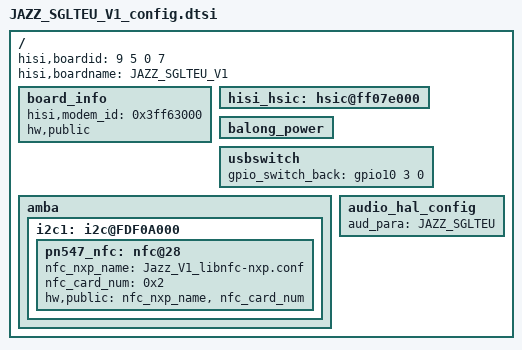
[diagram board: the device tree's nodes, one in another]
/*
 * Hisilicon Ltd.
 *
 * A15x4 A7x4
 *
 * It is only a demo for hisilicon hi3630 board. You show change the
 * address of each node according to datasheet.
 */


/include/ "hisi_3630_hsic.dtsi"
/include/ "huawei_usbswitch.dtsi"
/include/ "JAZZ_ULG_V1_config.dtsi"
/include/ "huawei_ext_modem.dtsi"

/ {
	hisi,boardid = <9 5 0 7>;
	hisi,boardname = "JAZZ_SGLTEU_V1";
	board_info: board_info {
		hisi,modem_id = <0x3ff63000>;
		hw,public;
	};
    hisi_hsic:hsic@ff07e000 {
        status = "ok";
    };
    balong_power:balong_power {
        status = "ok";
    };
    usbswitch: usbswitch {
        gpio_switch_back = <&gpio10 3 0>;
        status = "ok";
    };
	amba {
		i2c1: i2c@FDF0A000 {
			pn547_nfc:nfc@28 {
					  nfc_nxp_name = "Jazz_V1_libnfc-nxp.conf";
					  nfc_card_num = <0x2>;
					  hw,public="nfc_nxp_name","nfc_card_num";
			};
		};
	};
	audio_hal_config {
		aud_para = "JAZZ_SGLTEU";
	};
};
